# MAX32550 register map
Vendor: Maxim Integrated; File version: 1.0
Registers are 32-bit, read-write, reset 0x0 unless marked. A register's access mark holds for its fields unless they carry their own. Offsets are from the block's base; [hi:lo] are bit positions; {n}, {i} and the like mark numbered series; 'fields as' and 'values as' point back to an identical list.

## GPIO_0 — Individual I/O for Port 0
Base 0x40008000; register names take the prefix GPIO0_
Same registers: GPIO_1 0x40009000 (register names take the prefix GPIO1_), GPIO_2 0x4000A000 (register names take the prefix GPIO2_)
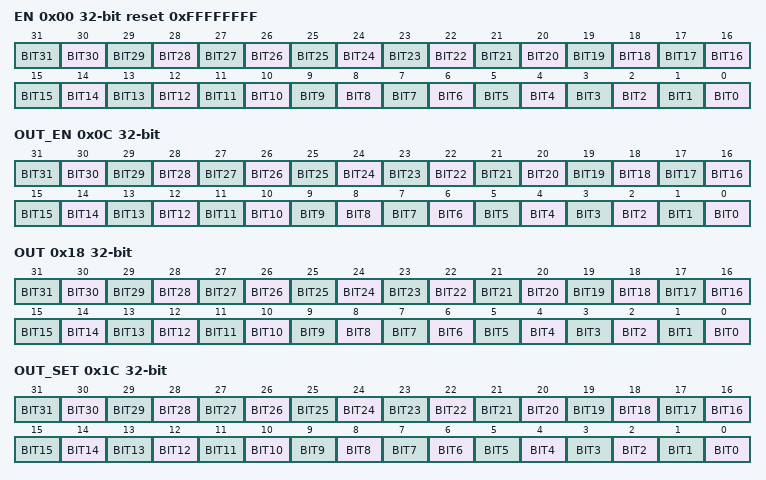
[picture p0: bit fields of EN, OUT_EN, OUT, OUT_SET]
0x00 EN reset 0xFFFFFFFF — GPIO Function Enable Register. Each bit controls the GPIO_EN setting for one GPIO pin on the associated port.
  [all] fields
    0=disable; 1=enable
  [n] BIT{n} (n=0..31)
0x0C OUT_EN — GPIO Output Enable Register. Each bit controls the GPIO_OUT_EN setting for one GPIO pin in the associated port.
  [all] fields
    0=disable; 1=enable
  [n] BIT{n} (n=0..31)
0x18 OUT — GPIO Output Register. Each bit controls the GPIO_OUT setting for one pin in the associated port. This register can be written either directly, or by using the GPIO_OUT_SET and GPIO_OUT_CLR registers.
  [all] fields
    0=lo (Logic 0 (low)); 1=hi (Logic 1 (high))
  [n] BIT{n} (n=0..31)
0x1C OUT_SET wo — GPIO Output Set. Writing a 1 to one or more bits in this register sets the bits in the same positions in GPIO_OUT to 1, without affecting other bits in that register.
  [all] fields
    0=nop (No effect); 1=set (Set bit in this position)
  [n] BIT{n} (n=0..31)
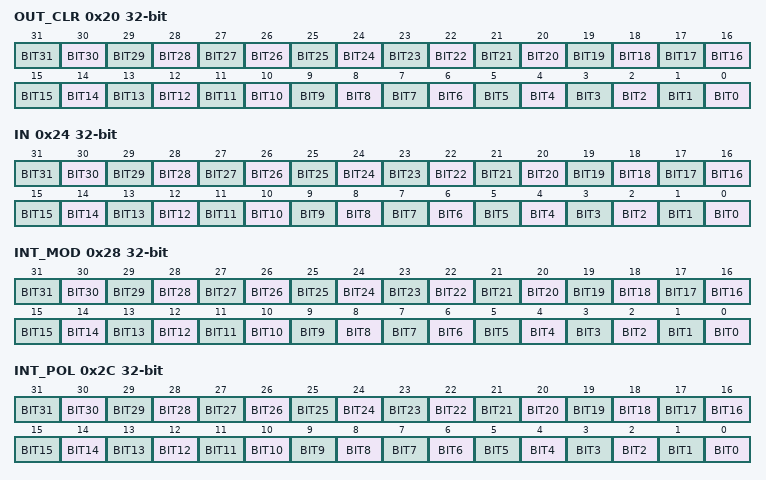
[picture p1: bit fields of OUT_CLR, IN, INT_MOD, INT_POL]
0x20 OUT_CLR wo — GPIO Output Clear. Writing a 1 to one or more bits in this register clears the bits in the same positions in GPIO_OUT to 0, without affecting other bits in that register.
  [all] fields
    0=nop (No effect); 1=Clear bit in this position
  [n] BIT{n} (n=0..31)
0x24 IN ro — GPIO Input Register. Read-only register to read from the logic states of the GPIO pins on this port.
  [all] fields
    0=lo (Logic 0 (low)); 1=hi (Logic 1 (high))
  [n] BIT{n} rw (n=0..31)
0x28 INT_MOD — GPIO Interrupt Mode Register. Each bit in this register controls the interrupt mode setting for the associated GPIO pin on this port.
  [all] fields
    0=level (Interrupts for this pin are level triggered.); 1=edge (Interrupts for this pin are edge triggered.)
  [n] BIT{n} (n=0..31)
0x2C INT_POL — GPIO Interrupt Polarity Register. Each bit in this register controls the interrupt polarity setting for one GPIO pin in the associated port.
  [all] fields
    0=lo (Interrupts are latched on a falling edge or low level condition for this pin.); 1=hi (Interrupts are latched on a rising edge or high level condition for this pin.)
  [n] BIT{n} (n=0..31)
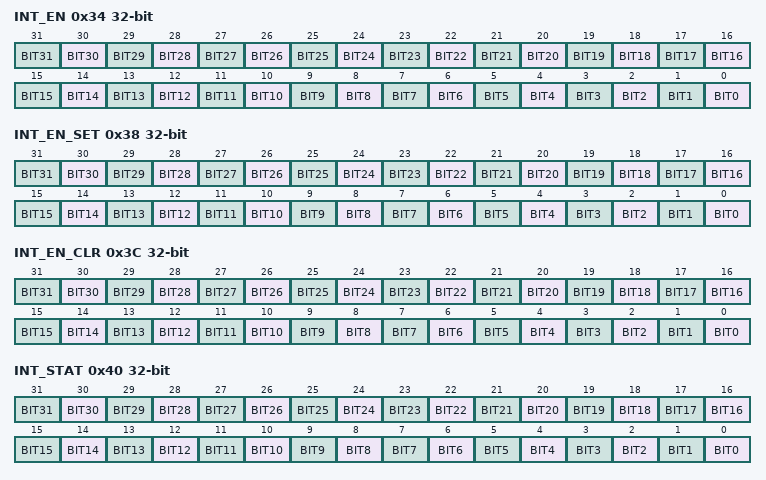
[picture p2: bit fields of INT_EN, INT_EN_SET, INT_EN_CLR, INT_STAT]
0x34 INT_EN — GPIO Interrupt Enable Register. Each bit in this register controls the GPIO interrupt enable for the associated pin on the GPIO port.
  [all] fields
    0=disable; 1=enable
  [n] BIT{n} (n=0..31)
0x38 INT_EN_SET wo — GPIO Interrupt Enable Set. Writing a 1 to one or more bits in this register sets the bits in the same positions in GPIO_INT_EN to 1, without affecting other bits in that register.
  fields as OUT_SET
0x3C INT_EN_CLR wo — GPIO Interrupt Enable Clear. Writing a 1 to one or more bits in this register clears the bits in the same positions in GPIO_INT_EN to 0, without affecting other bits in that register.
  fields as OUT_CLR
0x40 INT_STAT ro — GPIO Interrupt Status Register. Each bit in this register contains the pending interrupt status for the associated GPIO pin in this port.
  [all] fields
    0=inactive (No interrupt is pending.); 1=pending (An interrupt is pending.)
  [n] BIT{n} (n=0..31)
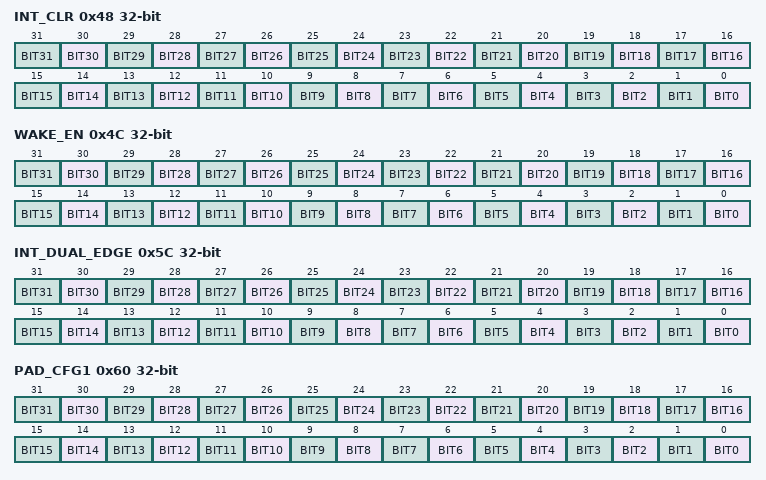
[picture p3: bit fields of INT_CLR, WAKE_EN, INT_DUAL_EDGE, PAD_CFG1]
0x48 INT_CLR wo — GPIO Interrupt Status Clear. Writing a 1 to one or more bits in this register clears the bits in the same positions in GPIO_INT_STAT to 0, without affecting other bits in that register.
  fields as OUT_CLR
0x4C WAKE_EN — GPIO Wake Enable Register. Each bit in this register controls the PMU wakeup enable for the associated GPIO pin in this port.
  [all] fields
    0=disable; 1=enable
  [n] BIT{n} (n=0..31)
0x5C INT_DUAL_EDGE — GPIO Interrupt Dual Edge Mode Register. Each bit in this register selects dual edge mode for the associated GPIO pin in this port.
  [all] fields
    0=disable; 1=enable
  [n] BIT{n} (n=0..31)
0x60 PAD_CFG1 — GPIO Input Mode Config 1. Each bit in this register enables the weak pull-up for the associated GPIO pin in this port.
  [all] fields
    0=disable; 1=enable
  [n] BIT{n} (n=0..31)
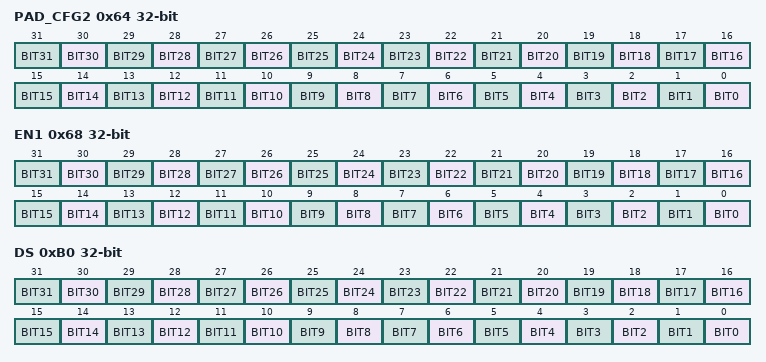
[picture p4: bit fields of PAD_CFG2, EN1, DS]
0x64 PAD_CFG2 — GPIO Input Mode Config 2. Each bit in this register enables the weak pull-down for the associated GPIO pin in this port.
  [all] fields
    0=disable; 1=enable
  [n] BIT{n} (n=0..31)
0x68 EN1 — GPIO Alternate Function Enable Register. Each bit in this register selects between primary/secondary functions for the associated GPIO pin in this port.
  [all] fields
    0=primary; 1=secondary
  [n] BIT{n} (n=0..31)
0xB0 DS — GPIO Drive Strength Register. Each bit in this register selects the drive strength for the associated GPIO pin in this port. Refer to the Datasheet for sink/source current of GPIO pins in each mode.
  [all] fields
    0=loDrive (GPIO port pin is in low-drive mode.); 1=hiDrive (GPIO port pin is in high-drive mode.)
  [n] BIT{n} (n=0..31)
